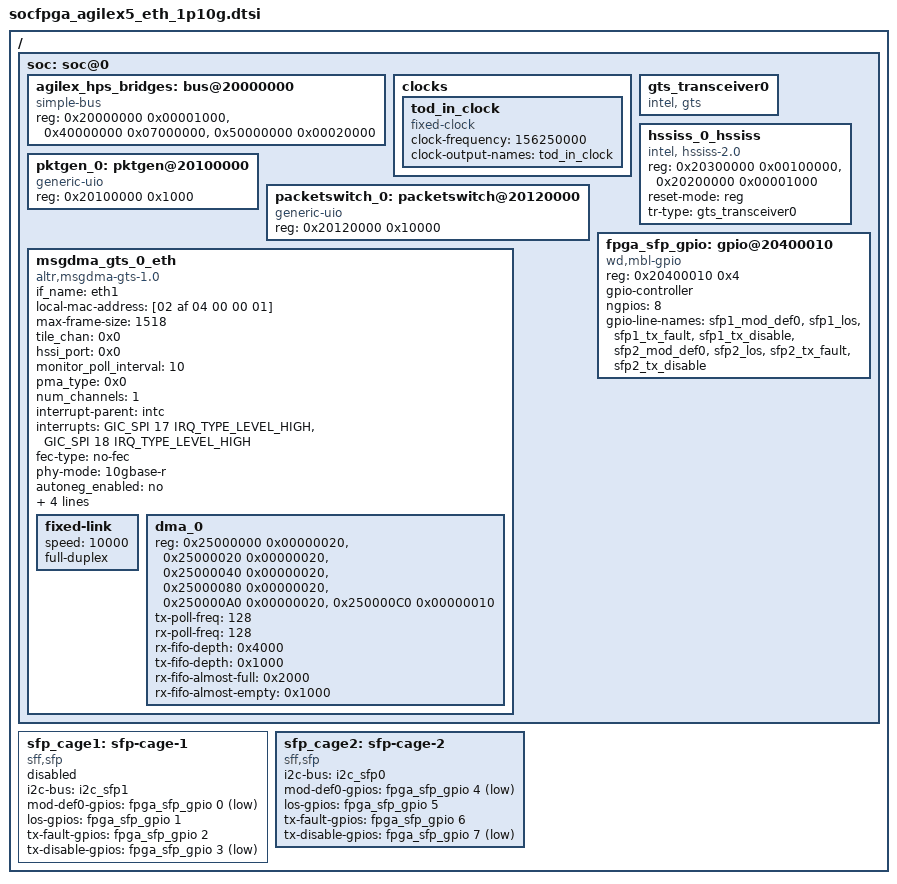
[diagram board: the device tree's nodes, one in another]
// SPDX-License-Identifier: GPL-2.0
/*
 * Copyright(C) 2024 Intel Corporation
 */

//original:
//user_csr 0x0020_0000  0x4020_0000  0x0000_1000
//qhip     0x0030_0000  0x4030_0000  0x0010_0000
//qsfpctrl 0x0404_0000  0x4404_0000  0x0000_4000
//msgdma   0x0500_0000  0x4500_0000  0x0000_0400
//pktcli   0x1000_0000  0x5000_0000  0x0000_1000
//pktsw    0x1001_0000  0x5001_0000  0x0001_0000

// new:
//          Offset       Absolute     Size
// user_csr 0x0020_0000  0x2020_0000  0x0000_1000
// qhip     0x0030_0000  0x2030_0000  0x0010_0000
// qsfpctrl Removed
// msgdma   0x0500_0000  0x2500_0000  0x0000_0400
// pktcli   0x0010_0000  0x2010_0000  0x0000_1000  // customer Qsys: csr_bridges_0.axi4lite_pktcli_0_s0
// pktsw    0x0011_0000  0x2011_0000  0x0001_0000  // customer Qsys: csr_bridges_0.axi4lite_ptpbridge_s0 / axi4lite_packetsw_m0


// FPGA DDR (2 Gbyte, still working on the other 2 Gbyte ...)
// 0x04_8000_0000 to 0x04_FFFF_FFFF

//The first 32-bit word in each ranges entry represents the child bus flags (or Chip Select / ID), which differentiates between the different physical AXI bridges or address spaces on the Agilex SoC.
//## Breakdown of the Values
//The node specifies #address-cells = <2>;, meaning a child address is made of two 32-bit words.
//
//* 0x00000000 points to the Lightweight HPS-to-FPGA (h2f_lw) bridge.
//* 0x00000001 points to the Main HPS-to-FPGA (h2f) data bridge.
//
//## How the ranges Format Works
//Each mapping inside ranges follows this structure based on your cell counts:
//[child-address-high] [child-address-low] [parent-address] [size]
//Here is how the first two entries map out:
//
//* Lightweight Bridge Mapping:
//
//<0x00000000 0x00000000 0x20000000 0x00001000>
// │          │          │          └─ Size (4KB)
// │          │          └─ Parent Base (0x20000000 in CPU space)
// └─┬────────┘
//   └─ Child Base Address (ID 0, offset 0x0)
//
//* Ethernet Subsystem Mapping:
//
//<0x00000001 0x40000000 0x40000000 0x04000000>
// │          │          │          └─ Size (64MB)
// │          │          └─ Parent Base (0x40000000 in CPU space)
// └─┬────────┘
//   └─ Child Base Address (ID 1, offset 0x40000000)
//
//
//## Why is it structured this way?
//Altera/Intel Agilex SoCs use these ID bits to let the Linux kernel drivers know which physical interconnect/bridge
//path a peripheral belongs to, allowing the system to accurately translate a peripheral's local register space back
//to the main CPU physical memory map.


/{
	soc: soc@0{
//		agilex_hps_bridges: bus@20000000 {
//                compatible = "simple-bus";
//                reg = <0x20000000 0x00001000>,
//                      <0x40000000 0x07000000>,
//		      <0x50000000 0x00020000>;
//                reg-names = "axi_h2f", "axi_h2f_lw";
//                #address-cells = <2>;
//                #size-cells = <1>;
//                ranges =    <0x00000000 0x00000000 0x20000000 0x00001000>, /*axi h2f_lw*/
//                            <0x00000001 0x40000000 0x40000000 0x04000000>, /*axi_h2f: Ethernet subsytem*/
//                            <0x00000001 0x44040000 0x44040000 0x00010000>, /*axi_h2f: QSFP Controller*/
//                            <0x00000001 0x44050000 0x44050000 0x00000040>, /*axi_h2f: Master ToD*/
//                            <0x00000001 0x45000000 0x45000000 0x00300000>, /*axi_h2f: mSGDMA Global CSR, Port CSR*/
//                            <0x00000001 0x50000000 0x50000000 0x00003000>, /*axi_h2f: Port0:HE, Pkt Mux, User CSR*/
//                            <0x00000001 0x50010000 0x50010000 0x00003000>; /*axi_h2f: Port1:HE, Pkt Mux, User CSR*/
//		};

/* The address mappings are taken from the Qsys external/altera/agilex5-ed-ethernet/a5e065b-mod-devkit-exp-prod/src/hw/src/qsys/qsys_top.qsys */
		agilex_hps_bridges: bus@20000000 {
                compatible = "simple-bus";
                reg = <0x20000000 0x00001000>,
                      <0x40000000 0x07000000>,
		      <0x50000000 0x00020000>;
                reg-names = "axi_h2f", "axi_h2f_lw";
                #address-cells = <2>;
                #size-cells = <1>;
				ranges =    <0x00000000 0x00000000 0x20000000 0x00001000>, /* customer Qsys: bridge root / h2f_lw */
					    <0x00000000 0x00200000 0x20200000 0x00001000>, /* customer Qsys: csr_bridges_0.user_space_csr_s0 */
					    <0x00000000 0x00300000 0x20300000 0x00100000>, /* customer Qsys: csr_bridges_0.qhip_port_0_s0 */
					    <0x00000000 0x05000000 0x25000000 0x00000400>, /* customer Qsys: subsys_msgdma.csr */
					    <0x00000000 0x00100000 0x20100000 0x00001000>, /* customer Qsys: csr_bridges_0.axi4lite_pktcli_0_s0 */
					    <0x00000000 0x00120000 0x20120000 0x00010000>; /* customer Qsys: csr_bridges_0.axi4lite_ptpbridge_s0 / axi4lite_packetsw_m0 */
                 status = "okay";
		};

	
	clocks {
		tod_in_clock: tod_in_clock {
			#clock-cells = <0>;
			compatible = "fixed-clock";
			clock-frequency = <156250000>;
			clock-output-names = "tod_in_clock";
            status = "okay";
		};
	};

	gts_transceiver0: gts_transceiver0 {
		compatible = "intel, gts";
        status = "okay";
	};

	hssiss_0_hssiss: hssiss_0_hssiss {
		compatible = "intel, hssiss-2.0";
		reg-names = "sscsr", "usr_csr";
		/* customer Qsys: hssiss subsystem base window */
		reg = <0x20300000 0x00100000>,
			<0x20200000 0x00001000>;
				
		reset-mode ="reg";
        status = "okay";
		tr-type = <&gts_transceiver0>;
	};

		pktgen_0: pktgen@20100000 { /* customer Qsys: csr_bridges_0.axi4lite_pktcli_0_s0 */
			compatible = "generic-uio";
			reg = <0x20100000 0x1000>;
			reg-names = "pkt_cli";
			status = "okay";
		};

		packetswitch_0: packetswitch@20120000 { /* customer Qsys: csr_bridges_0.axi4lite_ptpbridge_s0 / axi4lite_packetsw_m0 */
			compatible = "generic-uio";
			reg = <0x20120000 0x10000>;
			reg-names = "packetswitch";
			status = "okay";
		};

		// QSFP controller was present in the original design at 0x44040000,
		// but it is not part of the customer Qsys map, so it remains disabled.
		//sfp_eth0: sfp-eth0 {
		//    compatible = "altera,sfp-mem";
		//    reg-names = "sfp-mem-ctrl";
		//    reg = <0x44040000 0x00001000>;
		//    status = "okay";
		//};

		/*
		 New FPGA : 0x2040014 is RW (but no function). 0x20400010 is now data for input and output:
		 SFP status is located on address 0x20400010. Bit 2,1 and 0 is (sfp1_tx_fault, sfp1_los, sfp1_mod_det)
		 The working SFP is "SFP2" with status bit 6,5 and 4  (sfp2_tx_fault, sfp2_los, sfp2_mod_det).
		 Tx-disable is 0x20400010 bit 3 (SFP1 Tx-dis) and bit 7  (SFP2 Tx-dis).
		 */
		fpga_sfp_gpio: gpio@20400010 {
			compatible = "wd,mbl-gpio";
			reg = <0x20400010 0x4>;
			reg-names = "dat";
			gpio-controller;
			#gpio-cells = <2>;
			ngpios = <8>;
			gpio-line-names =
				"sfp1_mod_def0",
				"sfp1_los",
				"sfp1_tx_fault",
				"sfp1_tx_disable",
				"sfp2_mod_def0",
				"sfp2_los",
				"sfp2_tx_fault",
				"sfp2_tx_disable";
            status = "okay";
		};

		msgdma_gts_0_eth: msgdma_gts_0_eth {
			compatible = "altr,msgdma-gts-1.0";
			#address-cells = <1>;
			#size-cells = <1>;
			ranges;
			if_name = "eth1";
			/* Fixed, locally administered MAC (bit 1 of first octet set) so eth1 does not
			 * get a random address each boot. Same on every board - replace with a
			 * per-board address (U-Boot eth1addr / SoM 24MAC402 EUI-48) for production.
			 */
			local-mac-address = [02 af 04 00 00 01];

            /* Max MTU (driver treats it as MTU, also programmed into the MAC).
             * It's a quoute from software/workspace/linux-socfpga/drivers/net/ethernet/altera/intel_fpga_eth_main.c
             * The max frame size is 1518, a VLAN header would be additional 4 bytes and additional
             * headroom for alignment is 2 bytes, 2048 is just fine.
			 */
			max-frame-size = <1518>;
			tile_chan = <0x0>;
			hssi_port = <0x0>;
			monitor_poll_interval = <10>;
			pma_type = <0x0>; // FGT - 0x00, FHT = 0x1000
			num_channels = <1>;
			interrupt-parent = <&intc>;
			interrupt-names = "dma0_tx_irq", "dma0_rx_irq";
			/* customer Qsys: f2h_irq0 bit0=tx, bit1=rx -> SPI 17/18 */
			interrupts = <GIC_SPI 17 IRQ_TYPE_LEVEL_HIGH>, <GIC_SPI 18 IRQ_TYPE_LEVEL_HIGH>;
			fec-type="no-fec";
			phy-mode = "10gbase-r";
			autoneg_enabled = "no";
			fec-cw-pos-rx = <0x0>;
			ui-adj-interval = <250>;
            status = "okay";
			hssiss = <&hssiss_0_hssiss>;
			sfp = <&sfp_cage2>;
			fixed-link {
				speed = <10000>;
				full-duplex;
			};

            dma_0 {
                    reg-names =	"tx_pref"  ,
                            "tx_csr"   ,
                            "tx_fifo"  ,
                            "rx_pref"  ,
                            "rx_csr"   ,
                            "rx_fifo";
                    reg =	<0x25000000 0x00000020>,
                        <0x25000020 0x00000020>,
                        <0x25000040 0x00000020>,
                        <0x25000080 0x00000020>,
                        <0x250000A0 0x00000020>,
                        <0x250000C0 0x00000010>;
                    tx-poll-freq=<128>;
                    rx-poll-freq=<128>;
                    rx-fifo-depth = <0x4000>;
                    tx-fifo-depth = <0x1000>;
                    rx-fifo-almost-full = <0x2000>;
                    rx-fifo-almost-empty = <0x1000>;
                };
            };

		/*
		 * Current customer FPGA build is single-channel only:
		 * - Qsys exposes one subsys_msgdma CSR window at 0x25000000 (dma_0)
		 * - IRQs are f2h_irq0 bit0/bit1 only (mapped to SPI 17/18)
		 * - Top-level RTL uses NUM_CHANNELS=1 and only channel index [0]
		 *
		 * Do not define msgdma_gts_1_eth until the FPGA design adds a true
		 * second DMA/HSSI datapath and exports distinct CSR/IRQ resources.
		 */
     };

    // SFP cage nodes are left disabled because the customer Qsys map no
    // longer exposes the original QSFP controller window.
    sfp_cage1: sfp-cage-1 {
        compatible = "sff,sfp";
        i2c-bus = <&i2c_sfp1>;

        /* Bit 0, 1, 2 for Mod_Det, LOS, Tx_Fault */
        mod-def0-gpios   = <&fpga_sfp_gpio 0 GPIO_ACTIVE_LOW>;
        los-gpios        = <&fpga_sfp_gpio 1 GPIO_ACTIVE_HIGH>;
        tx-fault-gpios   = <&fpga_sfp_gpio 2 GPIO_ACTIVE_HIGH>;

        /* Bit 3 for Tx-Disable */
        tx-disable-gpios = <&fpga_sfp_gpio 3 GPIO_ACTIVE_LOW>;

		status = "disabled";
    };

	sfp_cage2: sfp-cage-2 {
		compatible = "sff,sfp";
		i2c-bus = <&i2c_sfp0>; 

		/* Bit 4, 5, 6 for Mod_Det, LOS, Tx_Fault */
        mod-def0-gpios   = <&fpga_sfp_gpio 4 GPIO_ACTIVE_LOW>;
        los-gpios        = <&fpga_sfp_gpio 5 GPIO_ACTIVE_HIGH>;
        tx-fault-gpios   = <&fpga_sfp_gpio 6 GPIO_ACTIVE_HIGH>;

		/* Bit 7 for Tx-Disable */
		tx-disable-gpios = <&fpga_sfp_gpio 7 GPIO_ACTIVE_LOW>;
		
        status = "okay";
	};
};
